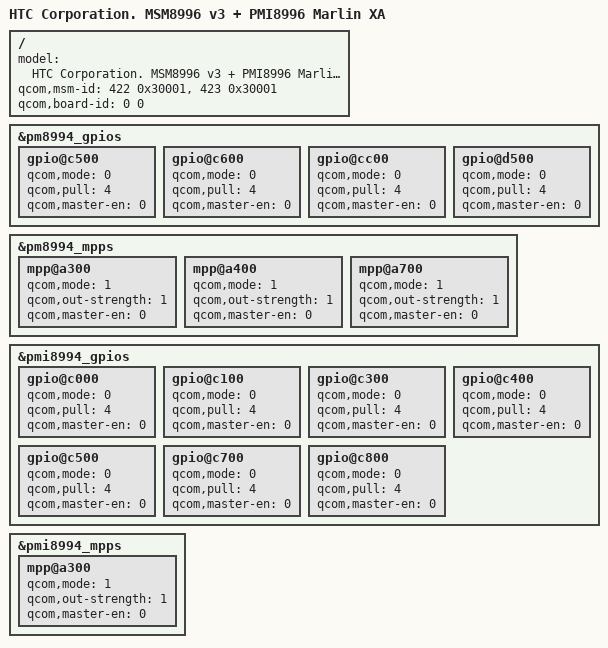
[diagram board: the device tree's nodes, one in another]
/* Copyright (c) 2015, The Linux Foundation. All rights reserved.
 *
 * This program is free software; you can redistribute it and/or modify
 * it under the terms of the GNU General Public License version 2 and
 * only version 2 as published by the Free Software Foundation.
 *
 * This program is distributed in the hope that it will be useful,
 * but WITHOUT ANY WARRANTY; without even the implied warranty of
 * MERCHANTABILITY or FITNESS FOR A PARTICULAR PURPOSE.  See the
 * GNU General Public License for more details.
 */


/dts-v1/;

#include "../qcom/msm8996-v3.dtsi"
#include "../qcom/msm-pmi8996.dtsi"
#include "../qcom/msm8996-mtp.dtsi"
#include "msm8996-nc-pins-htc_marlin-xa.dtsi"
#include "msm8996-htc_marlin.dtsi"

/ {
	model = "HTC Corporation. MSM8996 v3 + PMI8996 Marlin XA";
	qcom,msm-id = <422 0x30001>, <423 0x30001>;
	qcom,board-id = <0 0>;
};

&pm8994_gpios {
	gpio@c500 { /* GPIO 6 */
		qcom,mode = <0>;		/* Input	*/
		qcom,pull = <4>;		/* Pull DN	*/
		qcom,master-en = <0>;		/* Disable GPIO */
		status = "okay";		/* show status  */
	};
	gpio@c600 { /* GPIO 7 */
		qcom,mode = <0>;		/* Input	*/
		qcom,pull = <4>;		/* Pull DN	*/
		qcom,master-en = <0>;		/* Disable GPIO */
		status = "okay";		/* show status  */
	};
	gpio@cc00 { /* GPIO 13*/
		qcom,mode = <0>;		/* Input	*/
		qcom,pull = <4>;		/* Pull DN	*/
		qcom,master-en = <0>;		/* Disable GPIO */
		status = "okay";		/* show status  */
	};
	gpio@d500 { /* GPIO 22 */
		qcom,mode = <0>;		/* Input	*/
		qcom,pull = <4>;		/* Pull DN	*/
		qcom,master-en = <0>;		/* Disable GPIO */
		status = "okay";		/* show status  */
	};
};

&pm8994_mpps  {
	mpp@a300 { /* MPP 4 */
		qcom,mode = <1>;		/* Output	*/
		qcom,out-strength = <1>;	/* Low	*/
		qcom,master-en = <0>;		/* Disable MPP	*/
		status = "okay";		/* show status	*/
	};
	mpp@a400 { /* MPP 5 */
		qcom,mode = <1>;		/* Output	*/
		qcom,out-strength = <1>;	/* Low	*/
		qcom,master-en = <0>;		/* Disable MPP	*/
		status = "okay";		/* show status	*/
	};
	mpp@a700 { /* MPP 8 */
		qcom,mode = <1>;		/* Output	*/
		qcom,out-strength = <1>;	/* Low	*/
		qcom,master-en = <0>;		/* Disable MPP	*/
		status = "okay";		/* show status	*/
	};
};

&pmi8994_gpios{
	gpio@c000 { /* GPIO 1 */
		qcom,mode = <0>;		/* Input	*/
		qcom,pull = <4>;		/* Pull DN	*/
		qcom,master-en = <0>;		/* Disable GPIO */
		status = "okay";		/* show status  */
	};
	gpio@c100 { /* GPIO 2 */
		qcom,mode = <0>;		/* Input	*/
		qcom,pull = <4>;		/* Pull DN	*/
		qcom,master-en = <0>;		/* Disable GPIO */
		status = "okay";		/* show status  */
	};
	gpio@c300 { /* GPIO 4 */
		qcom,mode = <0>;		/* Input	*/
		qcom,pull = <4>;		/* Pull DN	*/
		qcom,master-en = <0>;		/* Disable GPIO */
		status = "okay";		/* show status  */
	};
	gpio@c400 { /* GPIO 5 */
		qcom,mode = <0>;		/* Input	*/
		qcom,pull = <4>;		/* Pull DN	*/
		qcom,master-en = <0>;		/* Disable GPIO */
		status = "okay";		/* show status  */
	};
	gpio@c500 { /* GPIO 6 */
		qcom,mode = <0>;		/* Input	*/
		qcom,pull = <4>;		/* Pull DN	*/
		qcom,master-en = <0>;		/* Disable GPIO */
		status = "okay";		/* show status  */
	};
	gpio@c700 { /* GPIO 8 */
		qcom,mode = <0>;		/* Input	*/
		qcom,pull = <4>;		/* Pull DN	*/
		qcom,master-en = <0>;		/* Disable GPIO */
		status = "okay";		/* show status  */
	};
	gpio@c800 { /* GPIO 9 */
		qcom,mode = <0>;		/* Input	*/
		qcom,pull = <4>;		/* Pull DN	*/
		qcom,master-en = <0>;		/* Disable GPIO */
		status = "okay";		/* show status	*/
	};
};

&pmi8994_mpps {
	mpp@a300 { /* MPP 4 */
		qcom,mode = <1>;		/* Output	*/
		qcom,out-strength = <1>;	/* Low	*/
		qcom,master-en = <0>;		/* Disable MPP	*/
		status = "okay";		/* show status	*/
	};
};

